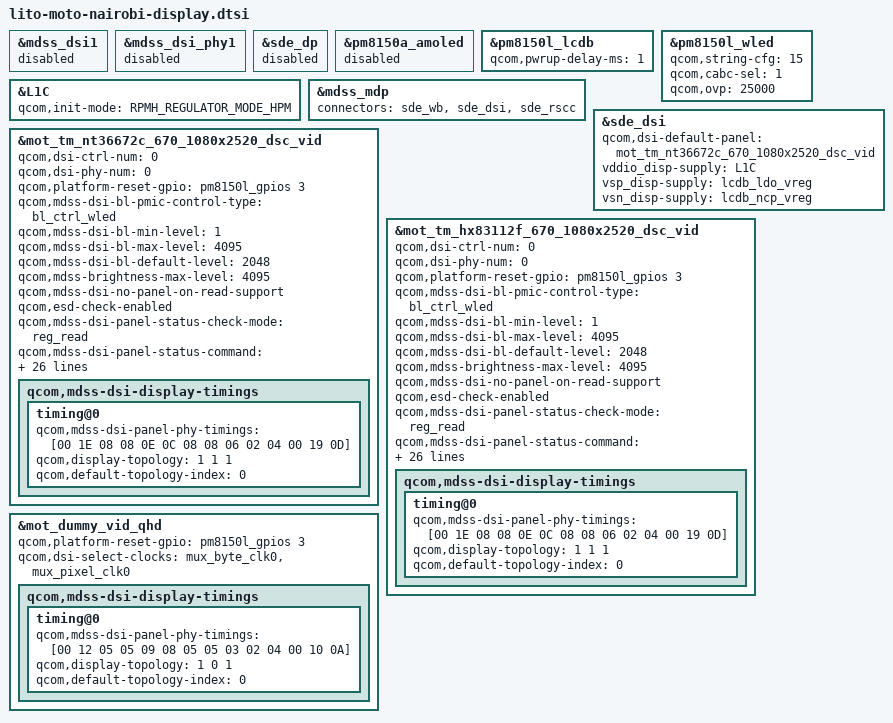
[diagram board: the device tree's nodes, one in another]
/* Copyright (c) 2019, The Linux Foundation. All rights reserved.
 *
 * This program is free software; you can redistribute it and/or modify
 * it under the terms of the GNU General Public License version 2 and
 * only version 2 as published by the Free Software Foundation.
 *
 * This program is distributed in the hope that it will be useful,
 * but WITHOUT ANY WARRANTY; without even the implied warranty of
 * MERCHANTABILITY or FITNESS FOR A PARTICULAR PURPOSE.  See the
 * GNU General Public License for more details.
 */
#include <dt-bindings/clock/mdss-7nm-pll-clk.h>
#include <dt-bindings/regulator/qcom,rpmh-regulator-levels.h>
#include "dsi-panel-mot-dummy-qhd-video.dtsi"
#include "lito-sde-display.dtsi"
#include "dsi-panel-mot-tianma-nt36672c-670-1080x2520-dsc-video.dtsi"
#include "dsi-panel-mot-tianma-hx83112f-670-1080x2520-dsc-video.dtsi"

&mdss_dsi1 {
	status = "disabled";
};

&mdss_dsi_phy1 {
	status = "disabled";
};

&sde_dp {
	status = "disabled";
};

&pm8150a_amoled {
	status = "disabled";
};

&pm8150l_lcdb {
	status = "ok";
	qcom,pwrup-delay-ms = <1>;
};

&pm8150l_wled {
	qcom,string-cfg = <15>;
	qcom,cabc-sel = <1>;
	qcom,ovp = <25000>;
	status = "ok";

	/delete-node/ wled_switch;
};

&L1C {
	/delete-property/ qcom,init-mode;
	qcom,init-mode = <RPMH_REGULATOR_MODE_HPM>;
};

&mdss_mdp {
	connectors = <&sde_wb &sde_dsi &sde_rscc>;
};

&sde_dsi {
	/delete-property/ qcom,dsi-default-panel;
	qcom,dsi-default-panel = <&mot_tm_nt36672c_670_1080x2520_dsc_vid>;

	vddio_disp-supply = <&L1C>;
	vsp_disp-supply = <&lcdb_ldo_vreg>;
	vsn_disp-supply = <&lcdb_ncp_vreg>;
};

&mot_tm_nt36672c_670_1080x2520_dsc_vid {
	qcom,dsi-ctrl-num = <0>;
	qcom,dsi-phy-num = <0>;

	qcom,platform-reset-gpio = <&pm8150l_gpios 3 0>;

	qcom,mdss-dsi-bl-pmic-control-type = "bl_ctrl_wled";
	qcom,mdss-dsi-bl-min-level = <1>;
	qcom,mdss-dsi-bl-max-level = <4095>;
	qcom,mdss-dsi-bl-default-level = <2048>;
	qcom,mdss-brightness-max-level = <4095>;

	qcom,mdss-dsi-no-panel-on-read-support;
	qcom,esd-check-enabled;
	qcom,mdss-dsi-panel-status-check-mode = "reg_read";
	qcom,mdss-dsi-panel-status-command = [06 01 00 01 00 00 01 0A];
	qcom,mdss-dsi-panel-status-command-state = "dsi_lp_mode";
	qcom,mdss-dsi-panel-status-value = <0x9c>;
	qcom,mdss-dsi-panel-status-read-length = <1>;

	qcom,mdss-dsi-panel-hdr-enabled;
	qcom,mdss-dsi-panel-hdr-color-primaries = <14500 15500 32000
	        17000 15500 30000 8000 3000>;
	qcom,mdss-dsi-panel-peak-brightness = <4200000>;
	qcom,mdss-dsi-panel-blackness-level = <4200>;

	qcom,tp_state_check_enable;

	qcom,mdss-dsi-pan-enable-dynamic-fps;
	qcom,mdss-dsi-pan-fps-update = "dfps_immediate_porch_mode_vfp";
	qcom,dsi-supported-dfps-list = <60 90>;

	qcom,mdss-dsi-hbm-on-command = [15 01 00 00 00 00 02 51 FF];
	qcom,mdss-dsi-hbm-on-command-state =  "dsi_lp_mode";
	qcom,mdss-dsi-hbm-off-command = [15 01 00 00 00 00 02 51 CC];
	qcom,mdss-dsi-hbm-off-command-state =  "dsi_lp_mode";
	qcom,mdss-dsi-hbm-type = "lcd-dcs-wled";

	qcom,dsi-select-clocks = "mux_byte_clk0", "mux_pixel_clk0";
	qcom,mdss-dsi-display-timings {
		timing@0 {
			/* Phy 4; w=1080 h=2520; 8bits 90hz; 3.75x dsc */
			qcom,mdss-dsi-panel-phy-timings = [00 1E 08 08 0E 0C 08
					08 06 02 04 00 19 0D];
			qcom,display-topology = <1 1 1>;
			qcom,default-topology-index = <0>;
		};
	};
};

&mot_tm_hx83112f_670_1080x2520_dsc_vid {
	qcom,dsi-ctrl-num = <0>;
	qcom,dsi-phy-num = <0>;

	qcom,platform-reset-gpio = <&pm8150l_gpios 3 0>;

	qcom,mdss-dsi-bl-pmic-control-type = "bl_ctrl_wled";
	qcom,mdss-dsi-bl-min-level = <1>;
	qcom,mdss-dsi-bl-max-level = <4095>;
	qcom,mdss-dsi-bl-default-level = <2048>;
	qcom,mdss-brightness-max-level = <4095>;

	qcom,mdss-dsi-no-panel-on-read-support;
	qcom,esd-check-enabled;
	qcom,mdss-dsi-panel-status-check-mode = "reg_read";
	qcom,mdss-dsi-panel-status-command = [14 01 00 01 00 00 01 0A];
	qcom,mdss-dsi-panel-status-command-state = "dsi_lp_mode";
	qcom,mdss-dsi-panel-status-value = <0x1D>;
	qcom,mdss-dsi-panel-status-read-length = <1>;

	qcom,mdss-dsi-panel-hdr-enabled;
	qcom,mdss-dsi-panel-hdr-color-primaries = <14500 15500 32000
	        17000 15500 30000 8000 3000>;
	qcom,mdss-dsi-panel-peak-brightness = <4200000>;
	qcom,mdss-dsi-panel-blackness-level = <4200>;

	qcom,tp_state_check_enable;

	qcom,mdss-dsi-pan-enable-dynamic-fps;
	qcom,mdss-dsi-pan-fps-update = "dfps_immediate_porch_mode_vfp";
	qcom,dsi-supported-dfps-list = <60 90>;

	qcom,mdss-dsi-hbm-on-command = [39 01 00 00 00 00 03 51 0F FF];
	qcom,mdss-dsi-hbm-on-command-state =  "dsi_lp_mode";
	qcom,mdss-dsi-hbm-off-command = [39 01 00 00 00 00 03 51 0C CC];
	qcom,mdss-dsi-hbm-off-command-state =  "dsi_lp_mode";
	qcom,mdss-dsi-hbm-type = "lcd-dcs-wled";

	qcom,dsi-select-clocks = "mux_byte_clk0", "mux_pixel_clk0";
	qcom,mdss-dsi-display-timings {
		timing@0 {
			/* Phy 4; w=1080 h=2520; 8bits 90hz; 3.75x dsc */
			qcom,mdss-dsi-panel-phy-timings = [00 1E 08 08 0E 0C 08
					08 06 02 04 00 19 0D];
			qcom,display-topology = <1 1 1>;
			qcom,default-topology-index = <0>;
		};
	};
};

&mot_dummy_vid_qhd {
	qcom,platform-reset-gpio = <&pm8150l_gpios 3 0>;

	qcom,dsi-select-clocks = "mux_byte_clk0", "mux_pixel_clk0";
	qcom,mdss-dsi-display-timings {
		timing@0 {
			qcom,mdss-dsi-panel-phy-timings = [00 12 05 05 09 08 05
							05 03 02 04 00 10 0A];
			qcom,display-topology = <1 0 1>;
			qcom,default-topology-index = <0>;
		};
	};
};
